# ATmega1284P register map
Vendor: Atmel; File version: 1.0
CPU: other r0p0, little endian, no MPU, no FPU, 4 interrupt priority bits
Registers are 8-bit, read-write, reset 0x0 unless marked. A register's access mark holds for its fields unless they carry their own. Offsets are from the block's base; [hi:lo] are bit positions; {n}, {i} and the like mark numbered series.

## EEPROM
Base 0x0080003F
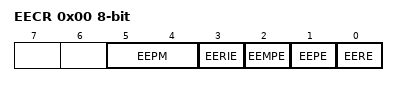
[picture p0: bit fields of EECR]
0x00 EECR — EEPROM Control Register
  [5:4] EEPM — EEPROM Programming Mode Bits
    0=ERASE_AND_WRITE_IN_ONE_OPERATION; 1=ERASE_ONLY; 2=WRITE_ONLY
  [3] EERIE — EEPROM Ready Interrupt Enable
  [2] EEMPE — EEPROM Master Write Enable
  [1] EEPE — EEPROM Write Enable
  [0] EERE — EEPROM Read Enable
0x01 EEDR — EEPROM Data Register
  [7:0] EEDR — EEPROM Data bits
0x02 EEAR 16-bit (reset mask 0xFF) — EEPROM Address Register Low Bytes
  [11:0] EEAR — EEPROM Address bits

## EXINT — External Interrupts
Base 0x0080003B
0x00 PCIFR — Pin Change Interrupt Flag Register (read-only for debugger)
  [3:0] PCIF — Pin Change Interrupt Flags
0x01 EIFR — External Interrupt Flag Register (read-only for debugger)
  [2:0] INTF — External Interrupt Flags
0x02 EIMSK — External Interrupt Mask Register
  [2:0] INT — External Interrupt Request 2 Enable
0x2D PCICR — Pin Change Interrupt Control Register
  [3:0] PCIE — Pin Change Interrupt Enables
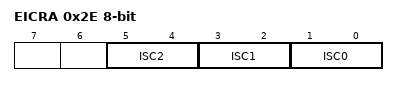
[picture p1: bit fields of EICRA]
0x2E EICRA — External Interrupt Control Register A
  [all] fields
    0=LOW_LEVEL_OF_INTX; 1=ANY_LOGICAL_CHANGE_OF_INTX; 2=FALLING_EDGE_OF_INTX; 3=RISING_EDGE_OF_INTX
  [5:4] ISC2 — External Interrupt Sense Control Bit
  [3:2] ISC1 — External Interrupt Sense Control Bit
  [1:0] ISC0 — External Interrupt Sense Control Bit
{0x30+i} PCMSK{i} (i=0..2) — Pin Change Mask Register {i}
  [7:0] PCINT — Pin Change Enable Masks
0x38 PCMSK3 — Pin Change Mask Register 3
  [7:0] PCINT — Pin Change Enable Masks

## JTAG — JTAG Interface
Base 0x00800051
0x00 OCDR — On-Chip Debug Related Register in I/O Memory (write-only for debugger)
0x03 MCUSR — MCU Status Register (read-only for debugger)
  [4] JTRF — JTAG Reset Flag
0x04 MCUCR — MCU Control Register
  [7] JTD — JTAG Interface Disable

## LOCKBIT — Lockbits
Base 0x00800000
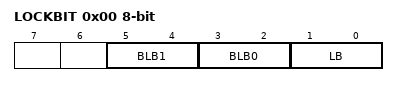
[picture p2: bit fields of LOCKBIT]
0x00 LOCKBIT
  [5:4] BLB1 — Boot Loader Protection Mode
    0=LPM_SPM_DISABLE (LPM and SPM prohibited in Boot Section); 1=LPM_DISABLE (LPM prohibited in Boot Section); 2=SPM_DISABLE (SPM prohibited in Boot Section); 3=NO_LOCK (No lock on SPM and LPM in Boot Section)
  [3:2] BLB0 — Boot Loader Protection Mode
    0=LPM_SPM_DISABLE (LPM and SPM prohibited in Application Section); 1=LPM_DISABLE (LPM prohibited in Application Section); 2=SPM_DISABLE (SPM prohibited in Application Section); 3=NO_LOCK (No lock on SPM and LPM in Application Section)
  [1:0] LB — Memory Lock
    0=PROG_VER_DISABLED (Further programming and verification disabled); 2=PROG_DISABLED (Further programming disabled); 3=NO_LOCK (No memory lock features enabled)

## PORTA — I/O Port
Base 0x00800020
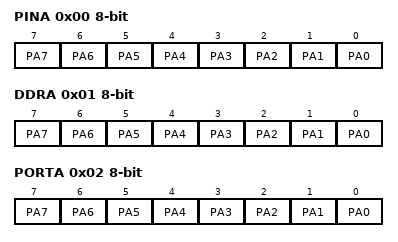
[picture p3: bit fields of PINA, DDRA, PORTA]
0x00 PINA — Port A Input Pins (read-only for debugger)
  [n] PA{n} (n=0..7) — Pin A{n}
0x01 DDRA — Port A Data Direction Register
  [n] PA{n} (n=0..7) — Pin A{n}
0x02 PORTA — Port A Data Register
  [n] PA{n} (n=0..7) — Pin A{n}

## PORTB — I/O Port
Base 0x00800023
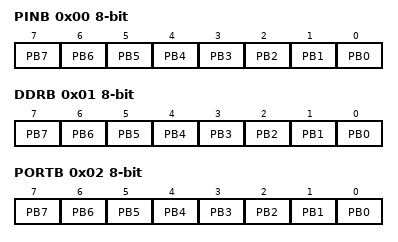
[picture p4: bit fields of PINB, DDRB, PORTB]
0x00 PINB — Port B Input Pins (read-only for debugger)
  [n] PB{n} (n=0..7) — Pin B{n}
0x01 DDRB — Port B Data Direction Register
  [n] PB{n} (n=0..7) — Pin B{n}
0x02 PORTB — Port B Data Register
  [n] PB{n} (n=0..7) — Pin B{n}

## PORTC — I/O Port
Base 0x00800026
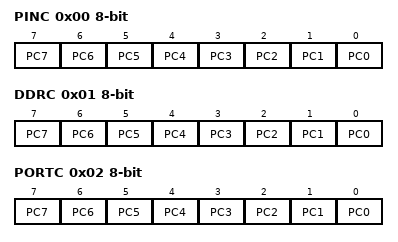
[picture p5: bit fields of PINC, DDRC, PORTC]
0x00 PINC — Port C Input Pins (read-only for debugger)
  [n] PC{n} (n=0..7) — Pin C{n}
0x01 DDRC — Port C Data Direction Register
  [n] PC{n} (n=0..7) — Pin C{n}
0x02 PORTC — Port C Data Register
  [n] PC{n} (n=0..7) — Pin C{n}

## PORTD — I/O Port
Base 0x00800029
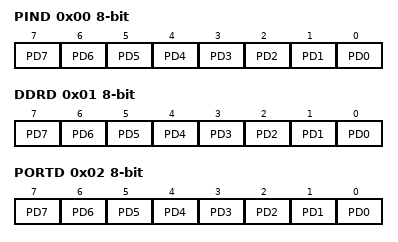
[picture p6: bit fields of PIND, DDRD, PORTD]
0x00 PIND — Port D Input Pins (read-only for debugger)
  [n] PD{n} (n=0..7) — Pin D{n}
0x01 DDRD — Port D Data Direction Register
  [n] PD{n} (n=0..7) — Pin D{n}
0x02 PORTD — Port D Data Register
  [n] PD{n} (n=0..7) — Pin D{n}
